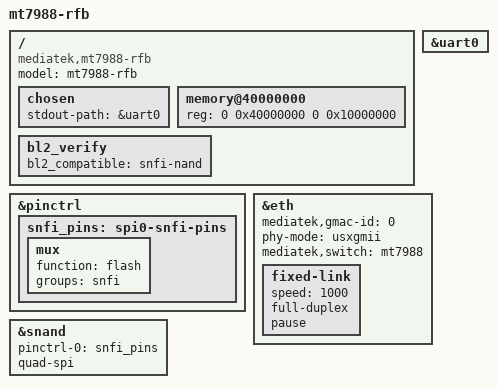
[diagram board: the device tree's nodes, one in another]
// SPDX-License-Identifier: GPL-2.0
/*
 * Copyright (c) 2021 MediaTek Inc.
 * Author: Sam Shih <sam.shih@mediatek.com>
 */

/dts-v1/;
#include "mt7988.dtsi"
#include <dt-bindings/gpio/gpio.h>

/ {
	model = "mt7988-rfb";
	compatible = "mediatek,mt7988-rfb", "mediatek,mt7988-snfi-nand-rfb";
	chosen {
		stdout-path = &uart0;
	};

	memory@40000000 {
		device_type = "memory";
		reg = <0 0x40000000 0 0x10000000>;
	};

	bl2_verify {
		bl2_compatible = "snfi-nand";
	};
};

&pinctrl {
	snfi_pins: spi0-snfi-pins {
		mux {
			function = "flash";
			groups = "snfi";
		};
	};
};

&uart0 {
	status = "okay";
};

&eth {
	status = "okay";
	mediatek,gmac-id = <0>;
	phy-mode = "usxgmii";
	mediatek,switch = "mt7988";

	fixed-link {
		speed = <1000>;
		full-duplex;
		pause;
	};
};

&snand {
	pinctrl-names = "default";
	pinctrl-0 = <&snfi_pins>;
	status = "okay";
	quad-spi;
};

